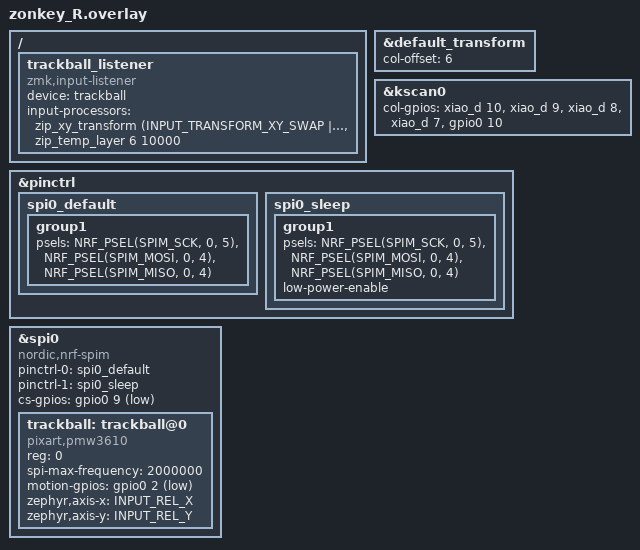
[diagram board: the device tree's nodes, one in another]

#include <input/processors.dtsi>
#include <dt-bindings/zmk/input_transform.h>
#include <dt-bindings/zmk/pointing.h>
#include "zonkey.dtsi"

/* スクロール値の再定義警告を回避 */
#undef ZMK_POINTING_DEFAULT_SCRL_VAL
#define ZMK_POINTING_DEFAULT_SCRL_VAL 100

&default_transform {
    col-offset = <6>;
};

&kscan0 {
    col-gpios
        = <&xiao_d 10 GPIO_ACTIVE_HIGH>
        , <&xiao_d 9 GPIO_ACTIVE_HIGH>
        , <&xiao_d 8 GPIO_ACTIVE_HIGH>
        , <&xiao_d 7 GPIO_ACTIVE_HIGH>
        , <&gpio0 10 GPIO_ACTIVE_HIGH>;
};

/ {
    trackball_listener {
        compatible = "zmk,input-listener";
        device = <&trackball>;

        /*
         * ZMK公式 input-processor
         *  - XY 入れ替え
         *  - Y 軸反転
         */
        input-processors =
            <&zip_xy_transform
             (INPUT_TRANSFORM_XY_SWAP | INPUT_TRANSFORM_Y_INVERT)>,
            <&zip_temp_layer 6 10000>;

    };
};

&pinctrl {
    spi0_default: spi0_default {
        group1 {
            psels = <NRF_PSEL(SPIM_SCK, 0, 5)>,
                    <NRF_PSEL(SPIM_MOSI, 0, 4)>,
                    <NRF_PSEL(SPIM_MISO, 0, 4)>;
        };
    };

    spi0_sleep: spi0_sleep {
        group1 {
            psels = <NRF_PSEL(SPIM_SCK, 0, 5)>,
                    <NRF_PSEL(SPIM_MOSI, 0, 4)>,
                    <NRF_PSEL(SPIM_MISO, 0, 4)>;
            low-power-enable;
        };
    };
};

&spi0 {
    status = "okay";
    compatible = "nordic,nrf-spim";
    pinctrl-0 = <&spi0_default>;
    pinctrl-1 = <&spi0_sleep>;
    pinctrl-names = "default", "sleep";
    cs-gpios = <&gpio0 9 GPIO_ACTIVE_LOW>;

    trackball: trackball@0 {
        status = "okay";
        compatible = "pixart,pmw3610";
        reg = <0>;
        spi-max-frequency = <2000000>;
        motion-gpios = <&gpio0 2 (GPIO_ACTIVE_LOW | GPIO_PULL_UP)>;

        /*
         * 軸定義は標準のまま
         * 向き補正は input-processor 側で処理
         */
        zephyr,axis-x = <INPUT_REL_X>;
        zephyr,axis-y = <INPUT_REL_Y>;
    };
};
